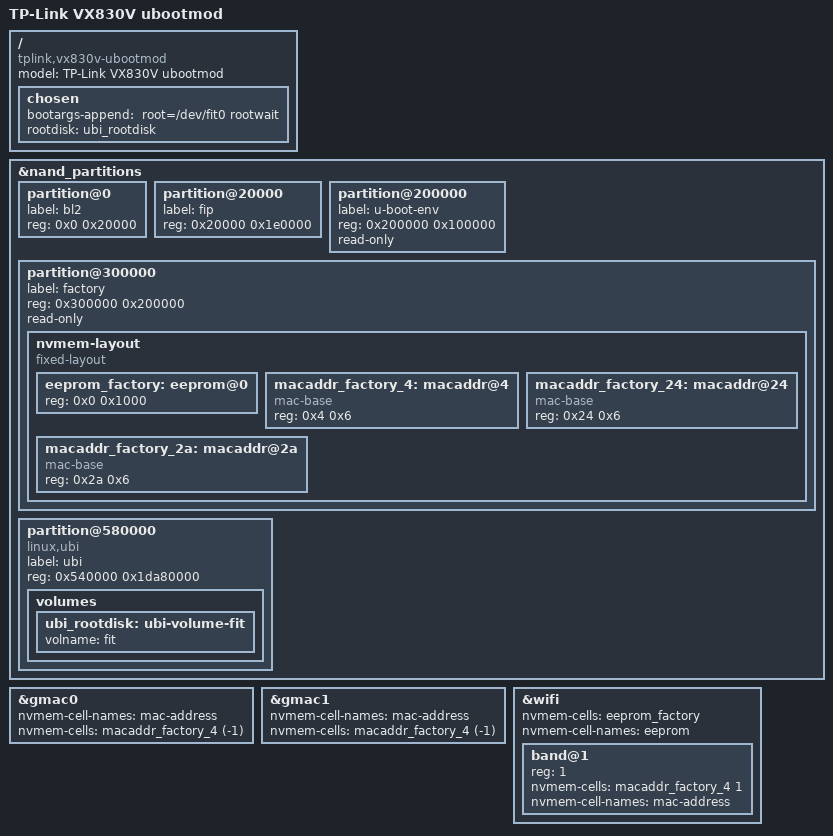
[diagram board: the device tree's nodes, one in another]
// SPDX-License-Identifier: GPL-2.0-or-later OR MIT
/*
 * Copyright (C) 2026 Nicolò Veronese <nicveronese@gmail.com>
 */

/dts-v1/;

#include "mt7986a-tplink-vx830v-common.dtsi"

/ {
	model = "TP-Link VX830V ubootmod";
	compatible = "tplink,vx830v-ubootmod", "mediatek,mt7986a";

	chosen {
		bootargs-append = " root=/dev/fit0 rootwait";
		rootdisk = <&ubi_rootdisk>;
	};
};

&nand_partitions {
	partition@0 {
		label = "bl2";
		reg = <0x0 0x20000>;             /* 128 KB (1 block)  | Ends: 0x20000 */
	};

	partition@20000 {
		label = "fip";
		reg = <0x20000 0x1e0000>;         /* 1.875 MB (15 blks)| Ends: 0x200000 */
	};

	partition@200000 {
		label = "u-boot-env";
		reg = <0x200000 0x100000>;        /* 1 MB (8 blocks)   | Ends: 0x300000 */
		read-only;
	};

	partition@300000 {
        label = "factory";
        reg = <0x300000 0x200000>;        /* 2 MB (16 blocks)  | Ends: 0x500000 */
        read-only;

		nvmem-layout {
			compatible = "fixed-layout";
			#address-cells = <1>;
			#size-cells = <1>;

			eeprom_factory: eeprom@0 {
				#size-cells = <1>;
				reg = <0x0 0x1000>;
			};

			macaddr_factory_4: macaddr@4 {
				compatible = "mac-base";
				reg = <0x4 0x6>;
				#nvmem-cell-cells = <1>;
			};

			macaddr_factory_24: macaddr@24 {
				compatible = "mac-base";
				reg = <0x24 0x6>;
				#nvmem-cell-cells = <1>;
			};

			macaddr_factory_2a: macaddr@2a {
				compatible = "mac-base";
				reg = <0x2a 0x6>;
				#nvmem-cell-cells = <1>;
			};
		};
	};

	partition@580000 {
		label = "ubi";
		reg = <0x540000 0x1da80000>;
		compatible = "linux,ubi";

		volumes {
			ubi_rootdisk: ubi-volume-fit {
				volname = "fit";
			};
		};
	};
};

&gmac0 {
	nvmem-cell-names = "mac-address";
	nvmem-cells = <&macaddr_factory_4 (-1)>;
};

&gmac1 {
	nvmem-cell-names = "mac-address";
	nvmem-cells = <&macaddr_factory_4 (-1)>;
};

&wifi {
	nvmem-cells = <&eeprom_factory>;
	nvmem-cell-names = "eeprom";

	band@1 {
		reg = <1>;
		nvmem-cells = <&macaddr_factory_4 1>;
		nvmem-cell-names = "mac-address";
	};
};
